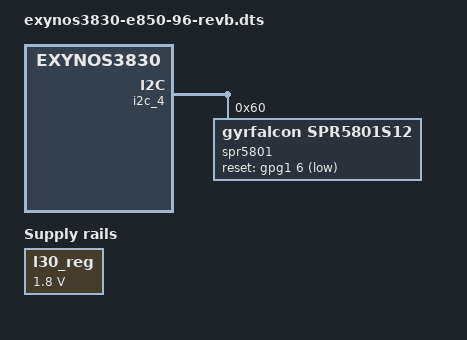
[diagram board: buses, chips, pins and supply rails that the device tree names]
/*
 * SAMSUNG EXYNOS3830 board device tree source
 *
 * Copyright (c) 2018 Samsung Electronics Co., Ltd.
 *		http://www.samsung.com
 *
 * This program is free software; you can redistribute it and/or modify
 * it under the terms of the GNU General Public License version 2 as
 * published by the Free Software Foundation.
 */

/dts-v1/;
/plugin/;

#define BOARD_ID	0x0
#define BOARD_REV	0x1

#include "exynos3830-e850-96-common.dtsi"

/* ---- AI chip nodes ------------------------------------------------------- */

&pinctrl_5 {
	spr5801_rst: spr5801_rst {
		samsung,pins = "gpg1-6";
		samsung,pin-function = <0x1>;	/* output */
		samsung,pin-pud = <0x3>;	/* pull-up */
	};
};

&i2c_4 {
	#address-cells = <1>;
	#size-cells = <0>;
	status = "okay";

	spr5801: spr5801@60 {
		compatible = "gyrfalcon,spr5801s12";
		reg = <0x60>;
		reset-gpios = <&gpg1 6 (GPIO_ACTIVE_LOW | GPIO_OPEN_DRAIN)>;
		pinctrl-names = "default";
		pinctrl-0 = <&spr5801_rst>;
	};
};

/* AI chip power: 1.8V, always keep power on */
&l30_reg {
	regulator-name = "vdd_ldo30";
	regulator-min-microvolt = <1800000>;
	regulator-max-microvolt = <1800000>;
	regulator-always-on;
	regulator-ramp-delay = <12000>;
	regulator-initial-mode = <3>;
};

/* ---- Audio nodes --------------------------------------------------------- */

/* Remove MCLK from UAIF0 (I2S0 lines) */
&abox_uaif_0 {
	compatible = "samsung,abox-uaif";
	reg = <0x0 0x14a50500 0x10>;
	reg-names = "sfr";
	samsung,id = <0>;
	clocks = <&clock DOUT_CLK_AUD_UAIF0>, <&clock GATE_ABOX_QCH_BCLK0>;
	clock-names = "bclk", "bclk_gate";
	pinctrl-names = "default", "sleep";
	pinctrl-0 = <&aud_i2s0_bus>;
	pinctrl-1 = <&aud_i2s0_idle>;
	#sound-dai-cells = <0>;
};

/* Enabled MCLK in UAIF1 (I2S1 lines) */
&abox_uaif_1 {
	compatible = "samsung,abox-uaif";
	reg = <0x0 0x14a50510 0x10>;
	reg-names = "sfr";
	samsung,id = <1>;
	clocks = <&clock DOUT_CLK_AUD_UAIF1>, <&clock GATE_ABOX_QCH_BCLK1>,
		 <&clock DOUT_CLK_AUD_MCLK>;
	clock-names = "bclk", "bclk_gate", "mclk";
	pinctrl-names = "default", "sleep";
	pinctrl-0 = <&aud_i2s1_bus &aud_codec_mclk>;
	pinctrl-1 = <&aud_i2s1_idle &aud_codec_mclk_idle>;
	#sound-dai-cells = <0>;
};
